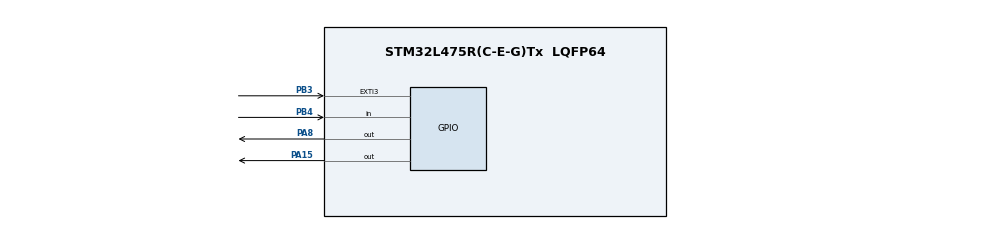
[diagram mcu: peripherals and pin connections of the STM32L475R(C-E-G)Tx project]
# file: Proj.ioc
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IWDG.Prescaler=IWDG_PRESCALER_128
IWDG.Reload=2300
Mcu.Family=STM32L4
Mcu.Name=STM32L475R(C-E-G)Tx
Mcu.Package=LQFP64
NVIC.EXTI3_IRQn=true\:0\:0\:false\:false\:true\:true\:true
NVIC.PriorityGroup=NVIC_PRIORITYGROUP_4
NVIC.TIM2_IRQn=true\:0\:0\:false\:false\:true\:true\:true
PA13\ (JTMS-SWDIO).Mode=Serial_Wire
PA13\ (JTMS-SWDIO).Signal=SYS_JTMS-SWDIO
PA14\ (JTCK-SWCLK).Mode=Serial_Wire
PA14\ (JTCK-SWCLK).Signal=SYS_JTCK-SWCLK
PA15\ (JTDI).Signal=GPIO_Output
PA8.Signal=GPIO_Output
PB3\ (JTDO-TRACESWO).GPIO_ModeDefaultEXTI=GPIO_MODE_IT_FALLING
PB3\ (JTDO-TRACESWO).GPIO_PuPd=GPIO_PULLUP
PB3\ (JTDO-TRACESWO).Signal=GPXTI3
PB4\ (NJTRST).Signal=GPIO_Input
PH0-OSC_IN\ (PH0).Mode=HSE-External-Oscillator
PH0-OSC_IN\ (PH0).Signal=RCC_OSC_IN
PH1-OSC_OUT\ (PH1).Mode=HSE-External-Oscillator
PH1-OSC_OUT\ (PH1).Signal=RCC_OSC_OUT
ProjectManager.HeapSize=0x200
ProjectManager.StackSize=0x400
ProjectManager.TargetToolchain=TrueSTUDIO
RCC.HSE_VALUE=8000000
RCC.HSI_VALUE=16000000
RCC.LSE_VALUE=32768
RCC.MSI_VALUE=4000000
RCC.VCOOutputFreq_Value=32000000
TIM2.Period=35999
TIM2.Prescaler=1999
VP_IWDG_VS_IWDG.Mode=IWDG_Activate
VP_TIM2_VS_ClockSourceINT.Mode=Internal
board=custom

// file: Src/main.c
/* USER CODE BEGIN Header */
/**
  ******************************************************************************
  * @file           : main.c
  * @brief          : Main program body
  ******************************************************************************
  * @attention
  *
  * <h2><center>&copy; Copyright (c) 2020 STMicroelectronics.
  * All rights reserved.</center></h2>
  *
  * This software component is licensed by ST under BSD 3-Clause license,
  * the "License"; You may not use this file except in compliance with the
  * License. You may obtain a copy of the License at:
  *                        opensource.org/licenses/BSD-3-Clause
  *
  ******************************************************************************
  */
/* USER CODE END Header */

#include "main.h"

IWDG_HandleTypeDef hiwdg;

TIM_HandleTypeDef htim2;

void SystemClock_Config(void);
static void MX_GPIO_Init(void);
static void MX_IWDG_Init(void);
static void MX_TIM2_Init(void);

/* USER CODE BEGIN 0 */
uint8_t tim2_count=0;

void __attribute__((optimize("O0"))) HAL_TIM_PeriodElapsedCallback(TIM_HandleTypeDef *htim)
{
  if(htim==&htim2)
  {
	  HAL_GPIO_TogglePin(GPIOA, GPIO_PIN_8);
//	  HAL_GPIO_WritePin(LED1_GPIO_Port, LED1_Pin, GPIO_PIN_SET);
  }

}
/* USER CODE END 0 */

int __attribute__((optimize("O0"))) main(void)
{
  /* USER CODE BEGIN 1 */
	HAL_TIM_Base_Start_IT(&htim2);
  /* USER CODE END 1 */

  /* MCU Configuration--------------------------------------------------------*/

  /* Reset of all peripherals, Initializes the Flash interface and the Systick. */
  HAL_Init();

  /* Configure the system clock */
  SystemClock_Config();

  /* Initialize all configured peripherals */
  MX_GPIO_Init();
  MX_IWDG_Init();
  MX_TIM2_Init();
  /* USER CODE BEGIN 2 */
  tim2_count = 0;
  /* USER CODE END 2 */

  /* Infinite loop */
  /* USER CODE BEGIN WHILE */
  while (1)
  {
	  HAL_IWDG_Refresh(&hiwdg);

	  HAL_GPIO_WritePin(GPIOA, GPIO_PIN_8, GPIO_PIN_SET);
	  HAL_Delay(60);
	  HAL_GPIO_WritePin(GPIOA, GPIO_PIN_8, GPIO_PIN_RESET);
	  HAL_Delay(1000);
	  tim2_count++;
    /* USER CODE END WHILE */

  }
}

void SystemClock_Config(void)
{
  RCC_OscInitTypeDef RCC_OscInitStruct = {0};
  RCC_ClkInitTypeDef RCC_ClkInitStruct = {0};

  /** Initializes the CPU, AHB and APB busses clocks
  */
  RCC_OscInitStruct.OscillatorType = RCC_OSCILLATORTYPE_LSI|RCC_OSCILLATORTYPE_MSI;
  RCC_OscInitStruct.LSIState = RCC_LSI_ON;
  RCC_OscInitStruct.MSIState = RCC_MSI_ON;
  RCC_OscInitStruct.MSICalibrationValue = 0;
  RCC_OscInitStruct.MSIClockRange = RCC_MSIRANGE_6;
  RCC_OscInitStruct.PLL.PLLState = RCC_PLL_NONE;
  if (HAL_RCC_OscConfig(&RCC_OscInitStruct) != HAL_OK)
  {
    Error_Handler();
  }
  /** Initializes the CPU, AHB and APB busses clocks
  */
  RCC_ClkInitStruct.ClockType = RCC_CLOCKTYPE_HCLK|RCC_CLOCKTYPE_SYSCLK
                              |RCC_CLOCKTYPE_PCLK1|RCC_CLOCKTYPE_PCLK2;
  RCC_ClkInitStruct.SYSCLKSource = RCC_SYSCLKSOURCE_MSI;
  RCC_ClkInitStruct.AHBCLKDivider = RCC_SYSCLK_DIV1;
  RCC_ClkInitStruct.APB1CLKDivider = RCC_HCLK_DIV1;
  RCC_ClkInitStruct.APB2CLKDivider = RCC_HCLK_DIV1;

  if (HAL_RCC_ClockConfig(&RCC_ClkInitStruct, FLASH_LATENCY_0) != HAL_OK)
  {
    Error_Handler();
  }
  /** Configure the main internal regulator output voltage
  */
  if (HAL_PWREx_ControlVoltageScaling(PWR_REGULATOR_VOLTAGE_SCALE1) != HAL_OK)
  {
    Error_Handler();
  }
}

static void MX_IWDG_Init(void)
{

  hiwdg.Instance = IWDG;
  hiwdg.Init.Prescaler = IWDG_PRESCALER_128;
  hiwdg.Init.Window = 4095;
  hiwdg.Init.Reload = 2300;
  if (HAL_IWDG_Init(&hiwdg) != HAL_OK)
  {
    Error_Handler();
  }

}

static void MX_TIM2_Init(void)
{

  TIM_ClockConfigTypeDef sClockSourceConfig = {0};
  TIM_MasterConfigTypeDef sMasterConfig = {0};

  htim2.Instance = TIM2;
  htim2.Init.Prescaler = 1;
  htim2.Init.CounterMode = TIM_COUNTERMODE_UP;
  htim2.Init.Period = 3;
  htim2.Init.ClockDivision = TIM_CLOCKDIVISION_DIV1;
  htim2.Init.AutoReloadPreload = TIM_AUTORELOAD_PRELOAD_DISABLE;
  if (HAL_TIM_Base_Init(&htim2) != HAL_OK)
  {
    Error_Handler();
  }
  sClockSourceConfig.ClockSource = TIM_CLOCKSOURCE_INTERNAL;
  if (HAL_TIM_ConfigClockSource(&htim2, &sClockSourceConfig) != HAL_OK)
  {
    Error_Handler();
  }
  sMasterConfig.MasterOutputTrigger = TIM_TRGO_RESET;
  sMasterConfig.MasterSlaveMode = TIM_MASTERSLAVEMODE_DISABLE;
  if (HAL_TIMEx_MasterConfigSynchronization(&htim2, &sMasterConfig) != HAL_OK)
  {
    Error_Handler();
  }

}

static void MX_GPIO_Init(void)
{
  GPIO_InitTypeDef GPIO_InitStruct = {0};

  /* GPIO Ports Clock Enable */
  __HAL_RCC_GPIOH_CLK_ENABLE();
  __HAL_RCC_GPIOA_CLK_ENABLE();
  __HAL_RCC_GPIOB_CLK_ENABLE();

  /*Configure GPIO pin Output Level */
  HAL_GPIO_WritePin(GPIOA, GPIO_PIN_8|GPIO_PIN_15, GPIO_PIN_RESET);

  /*Configure GPIO pins : PA8 PA15 */
  GPIO_InitStruct.Pin = GPIO_PIN_8|GPIO_PIN_15;
  GPIO_InitStruct.Mode = GPIO_MODE_OUTPUT_PP;
  GPIO_InitStruct.Pull = GPIO_NOPULL;
  GPIO_InitStruct.Speed = GPIO_SPEED_FREQ_LOW;
  HAL_GPIO_Init(GPIOA, &GPIO_InitStruct);

  /*Configure GPIO pin : PB3 */
  GPIO_InitStruct.Pin = GPIO_PIN_3;
  GPIO_InitStruct.Mode = GPIO_MODE_IT_FALLING;
  GPIO_InitStruct.Pull = GPIO_PULLUP;
  HAL_GPIO_Init(GPIOB, &GPIO_InitStruct);

  /*Configure GPIO pin : PB4 */
  GPIO_InitStruct.Pin = GPIO_PIN_4;
  GPIO_InitStruct.Mode = GPIO_MODE_INPUT;
  GPIO_InitStruct.Pull = GPIO_NOPULL;
  HAL_GPIO_Init(GPIOB, &GPIO_InitStruct);

  /* EXTI interrupt init*/
  HAL_NVIC_SetPriority(EXTI3_IRQn, 0, 0);
  HAL_NVIC_EnableIRQ(EXTI3_IRQn);

}

void Error_Handler(void)
{
}

/************************ (C) COPYRIGHT STMicroelectronics *****END OF FILE****/
